# DISPC_VID1 register map
Vendor: Texas Instruments
Peripheral module from a debugger description file (folder 66AK2G0x_66AK2G1x).
Registers are 32-bit, access per field, reset 0x0 unless marked. A register's access mark holds for its fields unless they carry their own. Offsets are as the file gives them; lines under a group give offsets from that group; [hi:lo] are bit positions; {n}, {i} and the like mark numbered series; 'fields as' and 'values as' point back to an identical list; <NAME> marks a mode.

## DISPC_VID1
0x00 DISPC_VID1_ACCUH_0
  [23:0] HORIZONTALACCU rw — Horizontal initialization accu signed value.
0x08 DISPC_VID1_ACCUH2_0
  [23:0] HORIZONTALACCU rw — Horizontal initialization accu signed value
0x10 DISPC_VID1_ACCUV_0
  [23:0] VERTICALACCU rw — Vertical initialization accu signed value.
0x18 DISPC_VID1_ACCUV2_0
  [23:0] VERTICALACCU rw — Vertical initialization accu signed value.
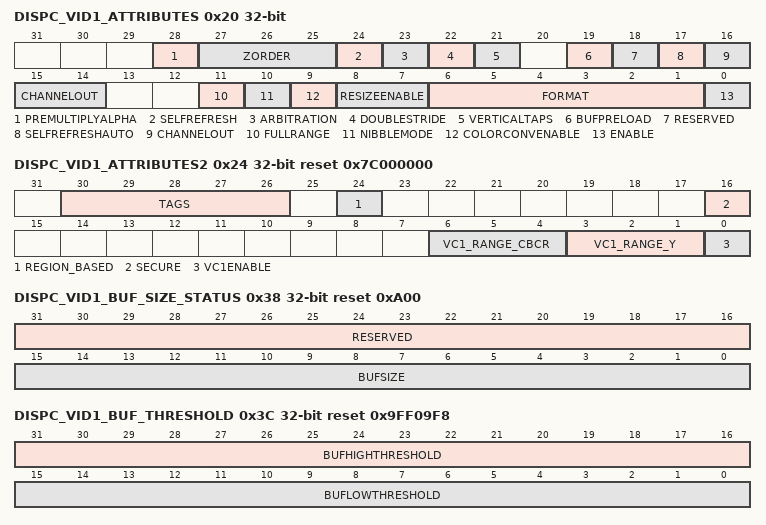
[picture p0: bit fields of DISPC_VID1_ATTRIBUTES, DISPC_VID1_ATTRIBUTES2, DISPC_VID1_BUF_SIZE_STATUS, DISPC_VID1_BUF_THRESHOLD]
0x20 DISPC_VID1_ATTRIBUTES
  [28] PREMULTIPLYALPHA rw — The field configures the DISPC VID1 to process incoming data as premultiplied alpha data or non premultiplied alpha data. Default setting is non premultiplied alpha data. 0h (R/W) = Non premultiplyalpha data color component 1h (R/W) = Premultiplyalpha data color component
  [27:25] ZORDER rw — Z-Order defining the priority of the layer compared to others when overlaying. It is SW responsibility to ensure that each layer connected to the same overlay manager has a different z-order value. 0h (R/W) = Z-order 0: layer above solid background color and below layer with higher Z-order values. 1h (R/W) = Z-order 1: layer above layer with z-order value of 0 and below layers with z-order values of 2 and 3 2h (R/W) = Z-order 2: layer above layers with z-order value of 0 and 1 and below layer with z-order value of 3 3h (R/W) = Z-order 3: layer above layers with z-order value of 0, 1 and 2 and below layer with z-order value of 4 4h (R/W) = Z-order 4: layer above layers with z-order value of 0, 1, 2 and 3 and below layer with z-order value of 5 5h (R/W) = Z-order 5: layer above all the other layers except cursor
  [24] SELFREFRESH rw — Enables the self refresh of the video window from its own DMA buffer only. 0h (R/W) = The video pipeline accesses the interconnect to fetch data from the system memory. 1h (R/W) = The video pipeline does not need anymore to fetch data from memory. Only the DMA buffer associated with the video1 is used. It takes effect after the frame has been loaded in the DMA buffer.
  [23] ARBITRATION rw — Determines the priority of the video pipeline. The video pipeline is one of the high priority pipeline. The arbitration gives always the priority first to the high priority pipelines using round-robin between them. When there is only normal priority pipelines sending requests, the round-robin applies between them. 0h (R/W) = The video pipeline is one of the normal priority pipeline. 1h (R/W) = The video pipeline is one of the high priority pipeline.
  [22] DOUBLESTRIDE rw — Determines if the stride for CbCr buffer is the 1x or 2x of the Y buffer stride. It is only used in case of YUV420 and 2D access 0h (R/W) = The CbCr stride value is equal to the Y stride. 1h (R/W) = The CbCr stride value is double to the Y stride.
  [21] VERTICALTAPS rw — Video Vertical Resize Tap Number. The vertial poly-phase filter can be configured in 3-tap or 5-tap configuration. According to the number of taps, the maximum input picture width is double while using 3-tap compared to 5-tap. 0h (R/W) = 3 taps are used for the vertical filtering logic. The 2 other taps are not used. The associated bit-fields for the 2 other taps coefficients do not need to be initialized. 1h (R/W) = 5 taps are used for the vertical filtering logic.
  [19] BUFPRELOAD rw — Video Preload Value 0h (R/W) = H/W prefetches pixels up to the preload value defined in the preload register 1h (R/W) = H/W prefetches pixels up to high threshold value
  [18] RESERVED ro — Write 0's for future compatibility. Reads return 0.
  [17] SELFREFRESHAUTO rw — Automatic self refresh mode 0h (R/W) = The transition from SELFREFRESH &lt;disabled&gt; to &lt;enabled&gt; is controlled by SW. 1h (R/W) = The transition from SELFREFRESH &lt;disabled&gt; to &lt;enabled&gt; is controlled only by HW.
  [16:14] CHANNELOUT rw — Video Channel Out configuration wr: immediate 0h (R/W) = OVR1 (VP1) Others = Reserved
  [11] FULLRANGE rw — Color Space Conversion full range setting. 0h (R/W) = Limited range selected: 16 subtracted from Y before color space conversion 1h (R/W) = Full range selected: Y is not modified before the color space conversion
  [10] NIBBLEMODE rw — Video Nibble mode (only for 1-, 2- and 4-bpp) 0h (R/W) = Nibble mode is disabled 1h (R/W) = Nibble mode is enabled
  [9] COLORCONVENABLE rw — Enable the color space conversion. The HW does not enable/disable the conversion based on the pixel format. The bit-field shall be reset when the format is not YUV. 0h (R/W) = Disable Color Space Conversion YUV to RGB 1h (R/W) = Enable Color Space Conversion YUV to RGB
  [8:7] RESIZEENABLE rw — Video Resize Enable 0h (R/W) = Disable both horizontal and vertical resize processing 1h (R/W) = Enable the horizontal resize processing 2h (R/W) = Enable the vertical resize processing 3h (R/W) = Enable both horizontal and vertical resize processing
  [6:1] FORMAT rw — Video Format. It defines the pixel format when fetching the video frame buffer. 0h (R/W) = ARGB16-4444 1h (R/W) = ABGR16-4444 2h (R/W) = RGBA16-4444 3h (R/W) = RGB16-565 4h (R/W) = BGR16-565 5h (R/W) = ARGB16-1555 6h (R/W) = ABGR16-1555 7h (R/W) = ARGB32-8888 8h (R/W) = ABGR32-8888 9h (R/W) = RGBA32-8888 Ah (R/W) = BGRA32-8888 Bh (R/W) = RGB24-888 (24-bit container) Ch - Dh (R/W) = RESERVED Eh (R/W) = ARGB32-2101010 Fh (R/W) = ABGR32-2101010 10h (R/W) = ARGB64-16161616 11h (R/W) = RGBA64_16161616 12h (R/W) = BITMAP1 (CLUT is required) 13h (R/W) = BITMAP2 (CLUT is required) 14h (R/W) = BITMAP4 (CLUT is required) 15h (R/W) = BITMAP8 (CLUT is required) 16h (R/W) = RGB565A8 17h (R/W) = BGR565A8 18h - 1Fh (R/W) = RESERVED1 20h (R/W) = xRGB12-4444 21h (R/W) = xBGR16-4444 22h (R/W) = RGBx16-4444 23h (R/W) = RESERVED2 25h (R/W) = xRGB16-1555 26h (R/W) = xBGR16-1555 27h (R/W) = xRGB32-8888 (32-bit container) 28h (R/W) = xBGR32_8888 29h (R/W) = RGBx32-8888 (24-bit RGB aligned on MSB of the 32-bit container) 2Ah (R/W) = BGRX32_8888 2Bh - 2Dh (R/W) = RESERVED3 2Eh (R/W) = xRGB32-2101010 2Fh (R/W) = xBGR32-2101010 30h (R/W) = xRGB64-16161616 31h (R/W) = RGBX64_16161616 32h - 3Ch (R/W) = RESERVED4 3Dh (R/W) = NV12/N21 4:2:0 2 buffers (Y + UV) 3Eh (R/W) = YUV2 4:2:2 co-sited 3Fh (R/W) = UYVY 4:2:2 co-sited
  [0] ENABLE rw — Video pipeline Enable 0h (R/W) = Video disabled (video pipeline inactive and window not present) 1h (R/W) = Video enabled (video pipeline active and window present on the screen)
0x24 DISPC_VID1_ATTRIBUTES2 reset 0x7C000000
  [30:26] TAGS rw — Number of OCP TAGS to be used for the pipeline (from 1 to 32)
  [24] REGION_BASED rw — Enable region-based mechanism 0h (R/W) = DISABLE 1h (R/W) = ENABLE
  [16] SECURE rw — OCP requests corresponds to pipeline data are secure/unsecure. The bit-field can be modified only by secure transaction using MReqSecure qualifier.
  [6:4] VC1_RANGE_CBCR rw — Defines the VC1 range value for the CbCr component from 0 to 7.
  [3:1] VC1_RANGE_Y rw — Defines the VC1 range value for the Y component from 0 to 7.
  [0] VC1ENABLE rw — Enable/disable the VC1 range mapping processing. The bit-field is ignored if the format is not one of the supported YUV formats. 0h (R/W) = VC1 range mapping disabled 1h (R/W) = VC1 range mapping enabled
0x28 DISPC_VID1_BA_0 rw
  [31:0] BA — Video base address. When decompression is enabled bit[5-0] shall be set to 0. Base address of the video buffer (aligned on pixel size boundary except in case of RGB24 packed format, 4-pixel alignment is required; in case of YUV422, 2-pixel alignment is required, and YUV420, byte alignment is supported). In case of YUV 4:2:0 format, it indicates the base address of the Y buffer. Otherwise the bits indicate the corresponding bit address to access the SDRAM.
0x30 DISPC_VID1_BA_UV_0 rw
  [31:0] BA — Video base address alinged on 16-bit boundary. Base address of the UV video buffer used only in case of YUV420-NV12. Otherwise the bits indicated the corresponding bit address to access the SDRAM.
0x38 DISPC_VID1_BUF_SIZE_STATUS ro reset 0xA00
  [31:16] RESERVED — Write 0's for future compatibility. Reads return 0
  [15:0] BUFSIZE — Video DMA buffer Size in number of 128-bits
0x3C DISPC_VID1_BUF_THRESHOLD rw reset 0x9FF09F8
  [31:16] BUFHIGHTHRESHOLD — Video DMA buffer High Threshold. Number of 128-bits defining the threshold value.
  [15:0] BUFLOWTHRESHOLD — DMA buffer High Threshold. Number of 128-bits defining the threshold value.
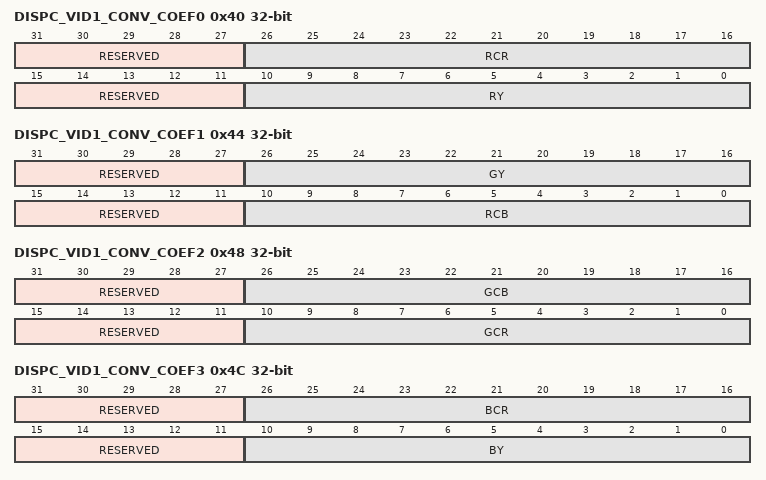
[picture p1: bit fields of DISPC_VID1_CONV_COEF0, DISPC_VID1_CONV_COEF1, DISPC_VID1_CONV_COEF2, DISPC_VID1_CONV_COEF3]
0x40 DISPC_VID1_CONV_COEF0
  [31:27] RESERVED ro — Write 0's for future compatibility. Reads return 0
  [26:16] RCR rw — RCr Coefficient Encoded signed value (from -1024 to 1023).
  [15:11] RESERVED ro — Write 0's for future compatibility. Reads return 0
  [10:0] RY rw — RY Coefficient Encoded signed value (from -1024 to 1023).
0x44 DISPC_VID1_CONV_COEF1
  [31:27] RESERVED ro — Write 0's for future compatibility. Reads return 0
  [26:16] GY rw — GY Coefficient Encoded signed value (from -1024 to 1023).
  [15:11] RESERVED ro — Write 0's for future compatibility. Reads return 0
  [10:0] RCB rw — RCb Coefficient Encoded signed value (from -1024 to 1023).
0x48 DISPC_VID1_CONV_COEF2
  [31:27] RESERVED ro — Write 0's for future compatibility. Reads return 0
  [26:16] GCB rw — GCb Coefficient Encoded signed value (from -1024 to 1023).
  [15:11] RESERVED ro — Write 0's for future compatibility. Reads return 0
  [10:0] GCR rw — GCr Coefficient Encoded signed value (from -1024 to 1023).
0x4C DISPC_VID1_CONV_COEF3
  [31:27] RESERVED ro — Write 0's for future compatibility. Reads return 0
  [26:16] BCR rw — BCr coefficient Encoded signed value (from -1024 to 1023).
  [15:11] RESERVED ro — Write 0's for future compatibility. Reads return 0
  [10:0] BY rw — BY coefficient Encoded signed value (from -1024 to 1023).
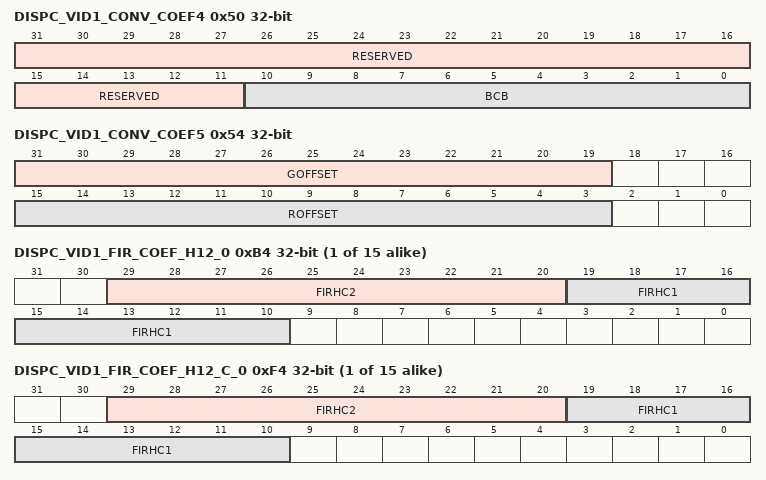
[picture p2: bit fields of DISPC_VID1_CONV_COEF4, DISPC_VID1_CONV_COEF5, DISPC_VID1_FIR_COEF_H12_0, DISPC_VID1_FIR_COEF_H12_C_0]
0x50 DISPC_VID1_CONV_COEF4
  [31:11] RESERVED ro — Write 0's for future compatibility. Reads return 0
  [10:0] BCB rw — BCb Coefficient Encoded signed value (from -1024 to 1023).
0x54 DISPC_VID1_CONV_COEF5
  [31:19] GOFFSET rw — G offset Encoded signed value (from -4096 to 4095).
  [15:3] ROFFSET rw — R offset Encoded signed value (from -4096 to 4095).
0x58 DISPC_VID1_CONV_COEF6
  [15:3] BOFFSET rw — B offset Encoded signed value (from -4096 to 4095).
0x5C DISPC_VID1_FIRH reset 0x200000
  [23:0] FIRHINC rw — Horizontal increment of the up/down-sampling filter. The value 0 is invalid.
0x60 DISPC_VID1_FIRH2 reset 0x200000
  [23:0] FIRHINC rw — Horizontal increment of the up/down-sampling filter for Cb and Cr. The value 0 is invalid.
0x64 DISPC_VID1_FIRV reset 0x200000
  [23:0] FIRVINC rw — Vertical increment of the up/down-sampling filter. The value 0 is invalid.
0x68 DISPC_VID1_FIRV2 reset 0x200000
  [23:0] FIRVINC rw — Vertical increment of the up/down-sampling filter for Cb and Cr. The value 0 is invalid.
{0x6C+4i} DISPC_VID1_FIR_COEF_H0_{i} (i=0..7)
  [9:0] FIRHC0 rw — Unsigned coefficient C0 for the horizontal up/down-scaling with the phase n
{0x90+4i} DISPC_VID1_FIR_COEF_H0_C_{i} (i=0..7)
  fields as DISPC_VID1_FIR_COEF_H0_0
{0xB4+4i} DISPC_VID1_FIR_COEF_H12_{i} (i=0..14)
  [29:20] FIRHC2 rw — Signed coefficient C2 for the horizontal up/down-scaling with the phase n
  [19:10] FIRHC1 rw — Signed coefficient C1 for the horizontal up/down-scaling with the phase n
{0xF4+4i} DISPC_VID1_FIR_COEF_H12_C_{i} (i=0..14)
  fields as DISPC_VID1_FIR_COEF_H12_0
{0x134+4i} DISPC_VID1_FIR_COEF_V0_{i} (i=0..7)
  [9:0] FIRVC0 rw — Unsigned coefficient C0 for the vertical up/down-scaling with the phase n
{0x158+4i} DISPC_VID1_FIR_COEF_V0_C_{i} (i=0..7)
  fields as DISPC_VID1_FIR_COEF_V0_0
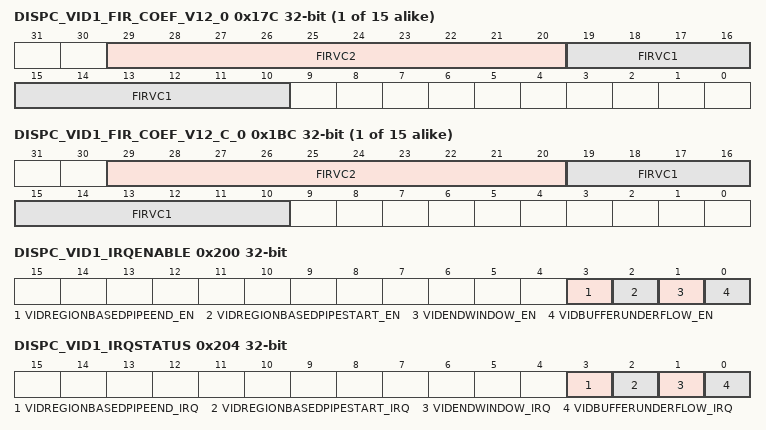
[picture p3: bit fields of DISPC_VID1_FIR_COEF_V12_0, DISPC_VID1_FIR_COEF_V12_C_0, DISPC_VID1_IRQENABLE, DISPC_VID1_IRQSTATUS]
{0x17C+4i} DISPC_VID1_FIR_COEF_V12_{i} (i=0..14)
  [29:20] FIRVC2 rw — Signed coefficient C2 for the vertical up/down-scaling with the phase n
  [19:10] FIRVC1 rw — Signed coefficient C1 for the vertical up/down-scaling with the phase n
{0x1BC+4i} DISPC_VID1_FIR_COEF_V12_C_{i} (i=0..14)
  fields as DISPC_VID1_FIR_COEF_V12_0
0x1FC DISPC_VID1_GLOBAL_ALPHA reset 0xFF
  [7:0] GLOBALALPHA rw — Global alpha value from 0 to 255. 0 corresponds to fully transparent and 255 to fully opaque.
0x200 DISPC_VID1_IRQENABLE
  [3] VIDREGIONBASEDPIPEEND_EN rw — PIPE end window IRQ for region-based feature 0h (R/W) = VIDREGIONBASEDPIPEEND is masked 1h (R/W) = VIDREGIONBASEDPIPEEND generates an interrupt when it occurs
  [2] VIDREGIONBASEDPIPESTART_EN rw — PIPE start window IRQ for region-based feature 0h (R/W) = VIDREGIONBASEDPIPESTART is masked 1h (R/W) = VIDREGIONBASEDPIPESTART generates an interrupt when it occurs
  [1] VIDENDWINDOW_EN rw — The end of the video Window has been reached. It is detected by the overlay manager when the full video has been displayed. 0h (R/W) = EndVid1Window is masked 1h (R/W) = EndVid1Window generates an interrupt when it occurs
  [0] VIDBUFFERUNDERFLOW_EN rw — Video DMA Buffer Underflow. The DMA buffer is not necessary empty but required data are not present in the DMA buffer (due to out of order responses) 0h (R/W) = Vid1BufferUnderflow is masked 1h (R/W) = Vid1BufferUnderflow generates an interrupt when it occurs
0x204 DISPC_VID1_IRQSTATUS
  [3] VIDREGIONBASEDPIPEEND_IRQ rw — PIPE end window IRQ for region-based feature 0h (R/W) = READS: Event is false. WRITES: Status bit unchanged. 1h (R/W) = READS: Event is true (pending). WRITES: Status bit is reset.
  [2] VIDREGIONBASEDPIPESTART_IRQ rw — PIPE start window IRQ for region-based feature 0h (R/W) = READS: Event is false. WRITES: Status bit unchanged. 1h (R/W) = READS: Event is true (pending). WRITES: Status bit is reset.
  [1] VIDENDWINDOW_IRQ rw — The end of the video Window has been reached. It is detected by the overlay manager when the full video has been displayed. 0h (R/W) = READS: Event is false. WRITES: Status bit unchanged. 1h (R/W) = READS: Event is true (pending). WRITES: Status bit is reset.
  [0] VIDBUFFERUNDERFLOW_IRQ rw — Video DMA Buffer Underflow. The DMA buffer is not necessarly empty but required data are not present in the DMA buffer (due to out of order responses) 0h (R/W) = READS: Event is false. WRITES: Status bit unchanged. 1h (R/W) = READS: Event is true (pending). WRITES: Status bit is reset.
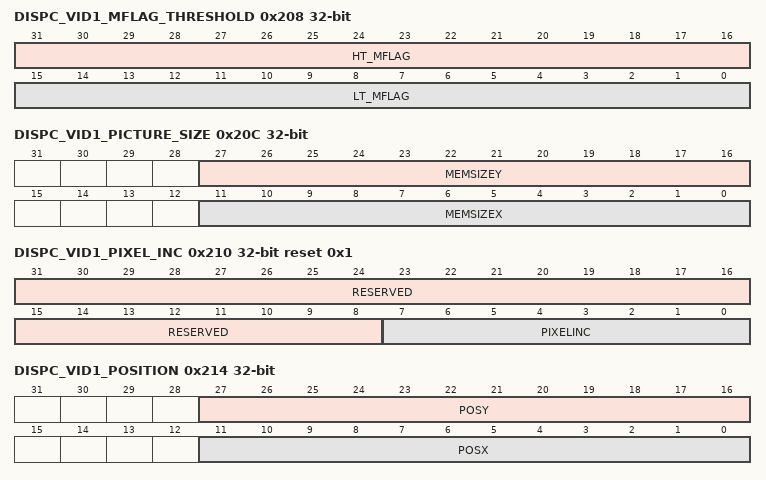
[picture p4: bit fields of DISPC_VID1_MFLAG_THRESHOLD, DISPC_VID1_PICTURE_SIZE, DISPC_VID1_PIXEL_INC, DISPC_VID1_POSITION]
0x208 DISPC_VID1_MFLAG_THRESHOLD rw
  [31:16] HT_MFLAG — High Thresholds (in 128bits) for MFLAG generation: when FIFO fullness reaches HT_MFLAG level, MFLAG is reset to 0
  [15:0] LT_MFLAG — Low Thresholds (in 128bits) for MFLAG generation: when FIFO fullness reaches LT_MFLAG level, MFLAG is set to 1
0x20C DISPC_VID1_PICTURE_SIZE
  [27:16] MEMSIZEY rw — Number of lines of the video picture Encoded value (from 1 to 4096) to specify the number of lines of the video picture in memory (program to value minus one). When predecimation is set, the value represents the size of the image after predecimation but the max size of the unpredecimated image size in memory is still bounded to 2exp(11).
  [11:0] MEMSIZEX rw — Number of pixels of the video picture Encoded value (from 1 to 4096) to specify the number of pixels of the video picture in memory (program to value minus one). The size is limited to the size of the line buffer of the vertical sampling block in case the video picture is processed by the vertical filtering unit. (program to value minus one). When predecimation is set, the value represents the size of the image after predecimation but the max size of the unpredecimated image size in memory is still bounded to 2exp(11).
0x210 DISPC_VID1_PIXEL_INC reset 0x1
  [31:8] RESERVED ro — Write 0's for future compatibility. Reads return 0
  [7:0] PIXELINC rw — Number of bytes to increment between two pixels. Encoded unsigned value (from 1 to 255) to specify the number of bytes between two pixels in the video buffer. The value 0 is invalid. The value 1 means next pixel. The value 1+n*bpp means increment of n pixels. For YUV420, Max supported value is 128.
0x214 DISPC_VID1_POSITION
  [27:16] POSY rw — Y position of the video window Encoded value (from 0 to 4095) to specify the Y position of the video window #1 .The line at the top has the Y-position 0.
  [11:0] POSX rw — X position of the video window Encoded value (from 0 to 4095) to specify the X position of the video window #1. The first pixel on the left of the display screen has the X-position 0.
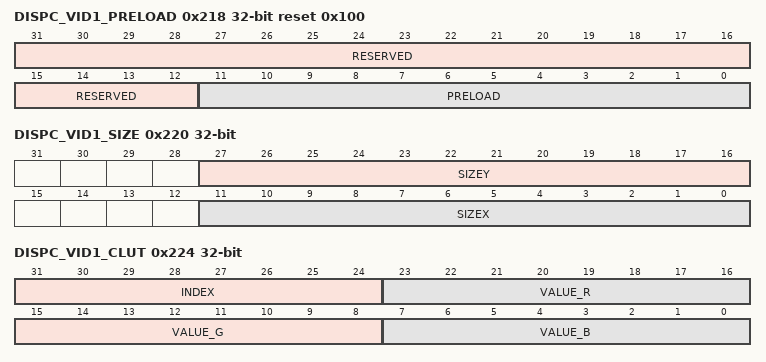
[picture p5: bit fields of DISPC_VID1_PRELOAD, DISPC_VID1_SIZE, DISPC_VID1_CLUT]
0x218 DISPC_VID1_PRELOAD reset 0x100
  [31:12] RESERVED ro — Write 0's for future compatibility. Reads return 0
  [11:0] PRELOAD rw — DMA buffer preload value Number of 128-bit words defining the preload value.
0x21C DISPC_VID1_ROW_INC rw reset 0x1
  [31:0] ROWINC — Number of bytes to increment at the end of the row Encoded signed value (from -2
0x220 DISPC_VID1_SIZE
  [27:16] SIZEY rw — Number of lines of the video window. Encoded value (from 1 to 4096) to specify the number of lines of the video window (program size -1).
  [11:0] SIZEX rw — Number of pixels of the video window. Encoded value (from 1 to 4096) to specify the number of pixels of the video window (program size -1).
0x224 DISPC_VID1_CLUT wo
  [31:24] INDEX — Defines the location in the table where the bit-field VALUE is stored
  [23:16] VALUE_R — 8-bit value used to defined the value to store at the location in the table defined by the bit-field INDEX.
  [15:8] VALUE_G — 8-bit value used to defined the value to store at the location in the table defined by the bit-field INDEX.
  [7:0] VALUE_B — 8-bit value used to defined the value to store at the location in the table defined by the bit-field INDEX.
